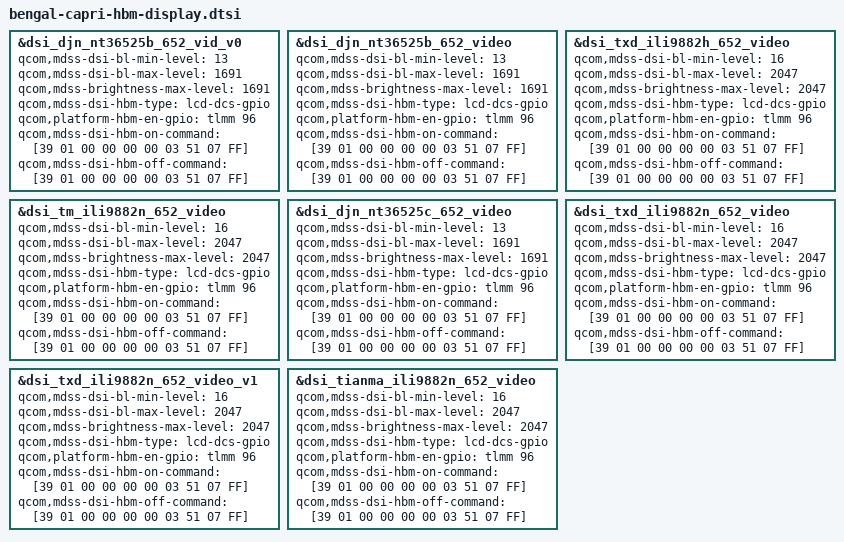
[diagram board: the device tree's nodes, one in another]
/* Copyright (c) 2020, The Linux Foundation. All rights reserved.
 *
 * This program is free software; you can redistribute it and/or modify
 * it under the terms of the GNU General Public License version 2 and
 * only version 2 as published by the Free Software Foundation.
 *
 * This program is distributed in the hope that it will be useful,
 * but WITHOUT ANY WARRANTY; without even the implied warranty of
 * MERCHANTABILITY or FITNESS FOR A PARTICULAR PURPOSE.  See the
 * GNU General Public License for more details.
 */

&dsi_djn_nt36525b_652_vid_v0 {
	qcom,mdss-dsi-bl-min-level = <13>;
	qcom,mdss-dsi-bl-max-level = <1691>;
	qcom,mdss-brightness-max-level = <1691>;
	qcom,mdss-dsi-hbm-type = "lcd-dcs-gpio";
	qcom,platform-hbm-en-gpio = <&tlmm 96 0>;
	qcom,mdss-dsi-hbm-on-command = [39 01 00 00 00 00 03 51 07 FF];
	qcom,mdss-dsi-hbm-off-command = [39 01 00 00 00 00 03 51 07 FF];

	/delete-property/ qcom,mdss-dsi-panel-hbm-is-51cmd;
};

&dsi_djn_nt36525b_652_video {
	qcom,mdss-dsi-bl-min-level = <13>;
	qcom,mdss-dsi-bl-max-level = <1691>;
	qcom,mdss-brightness-max-level = <1691>;
	qcom,mdss-dsi-hbm-type = "lcd-dcs-gpio";
	qcom,platform-hbm-en-gpio = <&tlmm 96 0>;
	qcom,mdss-dsi-hbm-on-command = [39 01 00 00 00 00 03 51 07 FF];
	qcom,mdss-dsi-hbm-off-command = [39 01 00 00 00 00 03 51 07 FF];

	/delete-property/ qcom,mdss-dsi-panel-hbm-is-51cmd;
};

&dsi_txd_ili9882h_652_video {
	qcom,mdss-dsi-bl-min-level = <16>;
	qcom,mdss-dsi-bl-max-level = <2047>;
	qcom,mdss-brightness-max-level = <2047>;
	qcom,mdss-dsi-hbm-type = "lcd-dcs-gpio";
	qcom,platform-hbm-en-gpio = <&tlmm 96 0>;
        qcom,mdss-dsi-hbm-on-command = [39 01 00 00 00 00 03 51 07 FF];
        qcom,mdss-dsi-hbm-off-command = [39 01 00 00 00 00 03 51 07 FF];

	/delete-property/ qcom,mdss-dsi-panel-hbm-is-51cmd;
};

&dsi_tm_ili9882n_652_video {
        qcom,mdss-dsi-bl-min-level = <16>;
	qcom,mdss-dsi-bl-max-level = <2047>;
	qcom,mdss-brightness-max-level = <2047>;
	qcom,mdss-dsi-hbm-type = "lcd-dcs-gpio";
	qcom,platform-hbm-en-gpio = <&tlmm 96 0>;
        qcom,mdss-dsi-hbm-on-command = [39 01 00 00 00 00 03 51 07 FF];
        qcom,mdss-dsi-hbm-off-command = [39 01 00 00 00 00 03 51 07 FF];

	/delete-property/ qcom,mdss-dsi-panel-hbm-is-51cmd;
};

&dsi_djn_nt36525c_652_video {
	qcom,mdss-dsi-bl-min-level = <13>;
	qcom,mdss-dsi-bl-max-level = <1691>;
	qcom,mdss-brightness-max-level = <1691>;
	qcom,mdss-dsi-hbm-type = "lcd-dcs-gpio";
	qcom,platform-hbm-en-gpio = <&tlmm 96 0>;
        qcom,mdss-dsi-hbm-on-command = [39 01 00 00 00 00 03 51 07 FF];
        qcom,mdss-dsi-hbm-off-command = [39 01 00 00 00 00 03 51 07 FF];

	/delete-property/ qcom,mdss-dsi-panel-hbm-is-51cmd;
};

&dsi_txd_ili9882n_652_video {
        qcom,mdss-dsi-bl-min-level = <16>;
	qcom,mdss-dsi-bl-max-level = <2047>;
	qcom,mdss-brightness-max-level = <2047>;
	qcom,mdss-dsi-hbm-type = "lcd-dcs-gpio";
	qcom,platform-hbm-en-gpio = <&tlmm 96 0>;
        qcom,mdss-dsi-hbm-on-command = [39 01 00 00 00 00 03 51 07 FF];
        qcom,mdss-dsi-hbm-off-command = [39 01 00 00 00 00 03 51 07 FF];

	/delete-property/ qcom,mdss-dsi-panel-hbm-is-51cmd;
};

//Capri plus panel#2 txd_ili9882n v1
&dsi_txd_ili9882n_652_video_v1 {
        qcom,mdss-dsi-bl-min-level = <16>;
        qcom,mdss-dsi-bl-max-level = <2047>;
        qcom,mdss-brightness-max-level = <2047>;
        qcom,mdss-dsi-hbm-type = "lcd-dcs-gpio";
        qcom,platform-hbm-en-gpio = <&tlmm 96 0>;
        qcom,mdss-dsi-hbm-on-command = [39 01 00 00 00 00 03 51 07 FF];
        qcom,mdss-dsi-hbm-off-command = [39 01 00 00 00 00 03 51 07 FF];

        /delete-property/ qcom,mdss-dsi-panel-hbm-is-51cmd;
};

&dsi_tianma_ili9882n_652_video {
        qcom,mdss-dsi-bl-min-level = <16>;
	qcom,mdss-dsi-bl-max-level = <2047>;
	qcom,mdss-brightness-max-level = <2047>;
	qcom,mdss-dsi-hbm-type = "lcd-dcs-gpio";
	qcom,platform-hbm-en-gpio = <&tlmm 96 0>;
        qcom,mdss-dsi-hbm-on-command = [39 01 00 00 00 00 03 51 07 FF];
        qcom,mdss-dsi-hbm-off-command = [39 01 00 00 00 00 03 51 07 FF];

	/delete-property/ qcom,mdss-dsi-panel-hbm-is-51cmd;
};
